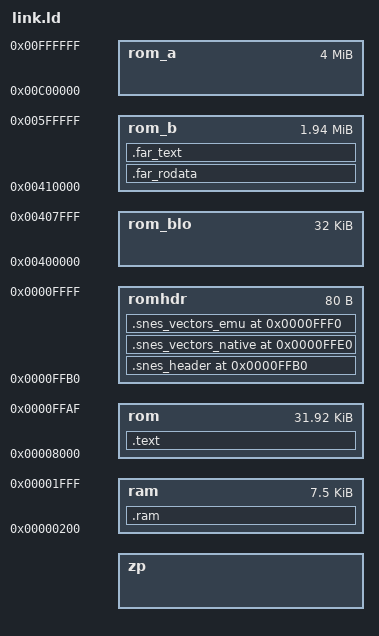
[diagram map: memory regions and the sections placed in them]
/* GENERATED by tools/snes-cartcanary.py from tools/snes_cartmap.py (exhirom, 0x600000). Do not edit by hand.
 *
 * Mapping        : exhirom, map mode $25
 * Image          : 6291456 bytes (48 Mbit)
 * Physical       : 32Mbit @ $000000 + 16Mbit @ $400000
 * Header at file : $40FFB0
 *
 * Canonical CPU windows (the ONE address a descriptor may name):
 *   $C0-$FF:0000-FFFF  <- file $000000-$3FFFFF
 *   $40-$5F:0000-FFFF  <- file $400000-$5FFFFF
 *
 * Boot model: the 65816 resets with PBR=$00 and fetches RESET from $00:FFFC.
 * Under ExHiROM banks $00-$3F upper halves are the SECOND region, so that
 * fetch reads file $40FFFC and the near window $00:8000-$FFFF is file
 * $408000-$40FFFF -- i.e. the boot code lives in bank $40, not bank $C0.
 * The unchanged crt0 still runs: it only needs $00:8000-$FFFF to be ROM.
 */

__rc0 = 0x00;
INCLUDE imag-regs.ld
ASSERT(__rc31 == 0x1f, "Inconsistent zero page map.")

__stack = 0x2000;

MEMORY {
  zp     : ORIGIN = __rc31 + 1, LENGTH = 0x100 - (__rc31 + 1)
  ram    : ORIGIN = 0x0200,     LENGTH = 0x1E00
  rom_a   : ORIGIN = 0xC00000, LENGTH = 0x400000   /* file $000000-$3FFFFF  region A: banks $C0-$FF, the first 4 MiB */
  rom_blo : ORIGIN = 0x400000, LENGTH = 0x008000   /* file $400000-$407FFF  bank $40 low half -- not mirrored into bank $00 */
  rom     : ORIGIN = 0x008000, LENGTH = 0x007FB0   /* file $408000-$40FFAF  near code: CPU $00:8000 == $40:8000 */
  romhdr  : ORIGIN = 0x00FFB0, LENGTH = 0x000050   /* file $40FFB0-$40FFFF  internal header + vectors */
  rom_b   : ORIGIN = 0x410000, LENGTH = 0x1F0000   /* file $410000-$5FFFFF  region B: banks $41-$7D */
}

REGION_ALIAS("c_readonly", rom)
REGION_ALIAS("c_writeable", ram)

SECTIONS {
  .text : { INCLUDE text-sections.ld } >c_readonly

  INCLUDE rodata.ld
  INCLUDE data.ld
  INCLUDE zp.ld
  INCLUDE bss.ld
  INCLUDE noinit.ld

  .ram (NOLOAD) : { *(.ram .ram.*) } >ram

  .far_rodata : { *(.far_rodata .far_rodata.*) } >rom_b
  .far_text   : { *(.far_text .far_text.*)     } >rom_b

  .snes_header 0xFFB0 : { KEEP(*(.snes_header)) } >romhdr

  .snes_vectors_native 0xFFE0 : {
    SHORT(0x0000) SHORT(0x0000)
    SHORT(0x0000) SHORT(irq)
    SHORT(0x0000) SHORT(nmi)
    SHORT(0x0000) SHORT(irq)
  } >romhdr

  .snes_vectors_emu 0xFFF0 : {
    SHORT(0x0000) SHORT(0x0000)
    SHORT(0x0000) SHORT(0x0000)
    SHORT(0x0000) SHORT(nmi)
    SHORT(_start) SHORT(irq)
  } >romhdr
}

/* Structural assertions: the header, the reset vector and both physical-ROM
 * boundaries must land where the model says, or the link fails loudly. */
ASSERT(ORIGIN(romhdr) == 0xFFB0, "header not at $FFB0")
ASSERT(LENGTH(rom) + LENGTH(romhdr) == 0x8000, "near window is not 32 KiB")
ASSERT(ORIGIN(rom_a) + 0x0 == 0xC00000, "physical ROM 1 does not start at its modelled CPU address")
ASSERT(ORIGIN(rom_blo) + 0x0 == 0x400000, "physical ROM 2 does not start at its modelled CPU address")

/* File order == the decoder model's offset order. */
OUTPUT_FORMAT {
  FULL(rom_a)
  FULL(rom_blo)
  FULL(rom)
  FULL(romhdr)
  FULL(rom_b)
}
